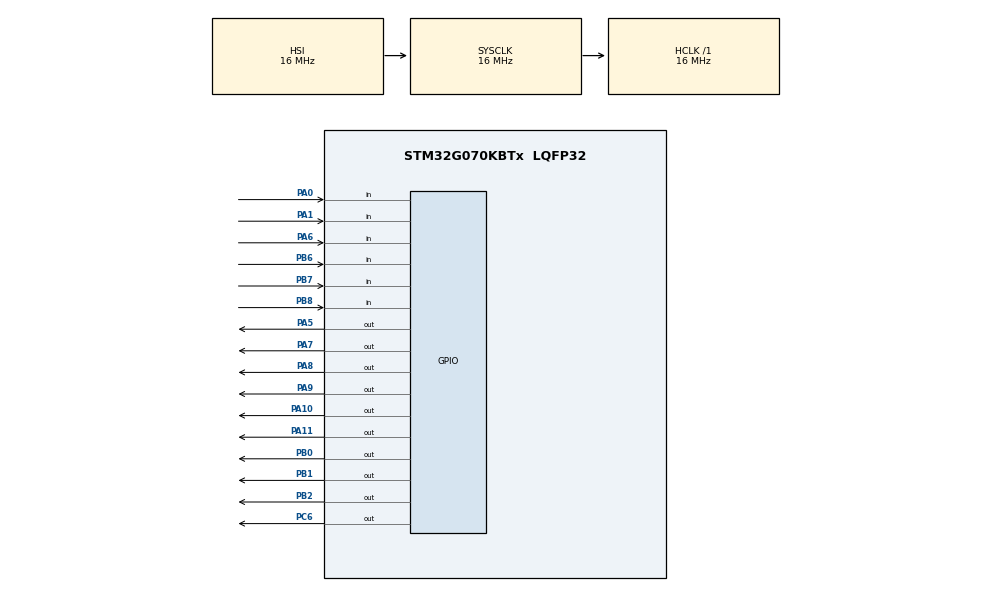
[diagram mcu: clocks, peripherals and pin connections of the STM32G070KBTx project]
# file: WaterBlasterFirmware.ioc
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Mcu.Family=STM32G0
Mcu.Name=STM32G070KBTx
Mcu.Package=LQFP32
PA0.Signal=GPIO_Input
PA1.Signal=GPIO_Input
PA10.Signal=GPIO_Output
PA11\ [PA9].Signal=GPIO_Output
PA13.Mode=Serial_Wire
PA13.Signal=SYS_SWDIO
PA14-BOOT0.Mode=Serial_Wire
PA14-BOOT0.Signal=SYS_SWCLK
PA5.Signal=GPIO_Output
PA6.Signal=GPIO_Input
PA7.Signal=GPIO_Output
PA8.Signal=GPIO_Output
PA9.Signal=GPIO_Output
PB0.Signal=GPIO_Output
PB1.Signal=GPIO_Output
PB2.Signal=GPIO_Output
PB6.Signal=GPIO_Input
PB7.Signal=GPIO_Input
PB8.Signal=GPIO_Input
PC6.Signal=GPIO_Output
ProjectManager.HeapSize=0x200
ProjectManager.StackSize=0x400
ProjectManager.TargetToolchain=STM32CubeIDE
RCC.AHBFreq_Value=16000000
RCC.CortexFreq_Value=16000000
RCC.EXTERNAL_CLOCK_VALUE=48000
RCC.HCLKFreq_Value=16000000
RCC.HSE_VALUE=8000000
RCC.HSI_VALUE=16000000
RCC.LSE_VALUE=32768
RCC.SYSCLKFreq_VALUE=16000000
RCC.VCOOutputFreq_Value=128000000
board=custom

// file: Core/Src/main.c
/* USER CODE BEGIN Header */
/**
  ******************************************************************************
  * @file           : main.c
  * @brief          : Main program body
  ******************************************************************************
  * @attention
  *
  * Copyright (c) 2025 STMicroelectronics.
  * All rights reserved.
  *
  * This software is licensed under terms that can be found in the LICENSE file
  * in the root directory of this software component.
  * If no LICENSE file comes with this software, it is provided AS-IS.
  *
  ******************************************************************************
  */
/* USER CODE END Header */
#include "main.h"
#include "newhaven_slim_oled.h"
#include "NHD_2066.h"
#include <stdio.h>
#include <string.h>

void SystemClock_Config(void);
static void MX_GPIO_Init(void);

/* USER CODE BEGIN PV */
uint8_t menu_mode = 0; // 0 = HOME, 1 = SETTINGS
uint8_t shot_count = 0;
uint32_t last_heartbeat = 0;
uint32_t last_valve_open_time = 0;
uint8_t valve_open = 0;
uint16_t valve_duration = 200;
uint8_t encoder_last_state = 0;

/* USER CODE END PV */

/* USER CODE BEGIN PFP */

ADC_HandleTypeDef hadc1;

int read_pressure_psi(void) {
    HAL_ADC_Start(&hadc1);

    if (HAL_ADC_PollForConversion(&hadc1, HAL_MAX_DELAY) != HAL_OK) {
        return -1;
    }

    uint32_t adc_raw_value = HAL_ADC_GetValue(&hadc1);
    float voltage = ((adc_raw_value * 3.3f) / 4095.0f) * 2.0f;

    if (voltage < 0.7f) voltage = 0.7f;
    if (voltage > 4.5f) voltage = 4.5f;

    float pressure = ((voltage - 0.7f) / 3.8f) * 150.0f;

    // Proper rounding for both positive and negative values
    if (pressure >= 0.0f)
        return (int)(pressure + 0.5f);
    else
        return (int)(pressure - 0.5f);
}

void update_heartbeat_led(void) {
    if (HAL_GetTick() - last_heartbeat >= 1000) {
        HAL_GPIO_TogglePin(GPIOC, GPIO_PIN_6);
        last_heartbeat = HAL_GetTick();
    }
}

void render_home_screen(int pressure) {
    NHD_OLED_textClear();
    char line[21];
    snprintf(line, sizeof(line), "Pressure: %3d PSI", pressure);
    NHD_OLED_print_len_pos(line, strlen(line), 0, 0);

    snprintf(line, sizeof(line), "Shots Remaining: %2d", shot_count);
    NHD_OLED_print_len_pos(line, strlen(line), 1, 0);

    int bar_len = (shot_count * 20) / 14;
    for (int i = 0; i < 20; ++i) {
        NHD_OLED_cursorPos(3, i);
        NHD_OLED_print_char(i < bar_len ? 0xFF : ' ');
    }
}

void render_settings_menu(void) {
    NHD_OLED_textClear();
    char line[21];
    snprintf(line, sizeof(line), "Burst Time: %4dms", valve_duration);
    NHD_OLED_print_len_pos(line, strlen(line), 1, 0);
    int bar_len = (valve_duration - 50) * 20 / (1000 - 50);
    for (int i = 0; i < 20; ++i) {
        NHD_OLED_cursorPos(3, i);
        NHD_OLED_print_char(i < bar_len ? 0xFF : ' ');
    }
}

int read_encoder_delta(void) {
    static uint8_t last_encoded = 0;
    uint8_t MSB = HAL_GPIO_ReadPin(GPIOA, GPIO_PIN_2);
    uint8_t LSB = HAL_GPIO_ReadPin(GPIOA, GPIO_PIN_3);
    uint8_t encoded = (MSB << 1) | LSB;
    uint8_t sum = (last_encoded << 2) | encoded;
    last_encoded = encoded;
    if (sum == 0b1101 || sum == 0b0100 || sum == 0b0010 || sum == 0b1011) return 1;
    if (sum == 0b1110 || sum == 0b0111 || sum == 0b0001 || sum == 0b1000) return -1;
    return 0;
}

void process_trigger(void) {
    if (shot_count > 0 && HAL_GPIO_ReadPin(GPIOA, GPIO_PIN_11) == GPIO_PIN_RESET) {
        HAL_GPIO_WritePin(GPIOA, GPIO_PIN_8, GPIO_PIN_SET);
        HAL_GPIO_WritePin(GPIOA, GPIO_PIN_9, GPIO_PIN_SET);
        last_valve_open_time = HAL_GetTick();
        valve_open = 1;
        shot_count--;
    }
    if (valve_open && HAL_GetTick() - last_valve_open_time >= valve_duration) {
        HAL_GPIO_WritePin(GPIOA, GPIO_PIN_8, GPIO_PIN_RESET);
        HAL_GPIO_WritePin(GPIOA, GPIO_PIN_9, GPIO_PIN_RESET);
        valve_open = 0;
    }
}

void process_pump(void) {
    if (HAL_GPIO_ReadPin(GPIOA, GPIO_PIN_1) == GPIO_PIN_RESET) {
        HAL_GPIO_WritePin(GPIOB, GPIO_PIN_2, GPIO_PIN_SET);
        HAL_GPIO_WritePin(GPIOA, GPIO_PIN_10, GPIO_PIN_SET);
    } else {
        HAL_GPIO_WritePin(GPIOB, GPIO_PIN_2, GPIO_PIN_RESET);
        HAL_GPIO_WritePin(GPIOA, GPIO_PIN_10, GPIO_PIN_RESET);
    }
}

void HAL_GPIO_EXTI_Callback(uint16_t GPIO_Pin) {
    if (GPIO_Pin == GPIO_PIN_4) {
        menu_mode ^= 1;
        HAL_Delay(200);
    }
}

int main(void)
{

  /* MCU Configuration--------------------------------------------------------*/

  /* Reset of all peripherals, Initializes the Flash interface and the Systick. */
  HAL_Init();

  /* Configure the system clock */
  SystemClock_Config();

  /* Initialize all configured peripherals */
  MX_GPIO_Init();

  /* Infinite loop */
  /* USER CODE BEGIN WHILE */
  HAL_GPIO_TogglePin(GPIOA, GPIO_PIN_10);
  /* USER CODE END 2 */

  /*
   * Set the reset to be high set
   * set the cs to be reset
   */
  HAL_GPIO_WritePin(GPIOB, GPIO_PIN_0, GPIO_PIN_RESET);
  HAL_GPIO_WritePin(GPIOB, GPIO_PIN_1, GPIO_PIN_SET);
//  HAL_GPIO_TogglePin(GPIOA, GPIO_PIN_8); // set the solenoid valve as closed on power on
  HAL_GPIO_TogglePin(GPIOA, GPIO_PIN_9); // set the solenoid valve as closed on power on
  NHD_OLED_begin();
  NHD_OLED_textClear();
  NHD_OLED_cursorHome();
  char* message = "Water Blaster";
  uint8_t length = 13;
  NHD_OLED_print_len(message, length);
  HAL_GPIO_TogglePin(GPIOA, GPIO_PIN_11);

  /* Infinite loop */
  /* USER CODE BEGIN WHILE */

////  NHD_OLED_displayOn();

  while (1==1)
  {

	if (HAL_GPIO_ReadPin(GPIOB, GPIO_PIN_6) == GPIO_PIN_RESET)
	{
	  HAL_GPIO_TogglePin(GPIOA, GPIO_PIN_9);
	  HAL_GPIO_TogglePin(GPIOA, GPIO_PIN_8);
	  HAL_Delay(50);
	  HAL_GPIO_TogglePin(GPIOA, GPIO_PIN_8);
	  HAL_GPIO_TogglePin(GPIOA, GPIO_PIN_9);
	}
	if (HAL_GPIO_ReadPin(GPIOA, GPIO_PIN_0) == GPIO_PIN_RESET)
	{
	  HAL_GPIO_TogglePin(GPIOB, GPIO_PIN_2);
	  HAL_GPIO_TogglePin(GPIOC, GPIO_PIN_6);
	  HAL_Delay(50);
	  HAL_GPIO_TogglePin(GPIOB, GPIO_PIN_2);
	  HAL_GPIO_TogglePin(GPIOC, GPIO_PIN_6);
	}
	if (HAL_GPIO_ReadPin(GPIOA, GPIO_PIN_1) == GPIO_PIN_RESET)
	{
	  HAL_GPIO_TogglePin(GPIOA, GPIO_PIN_9);
	  HAL_GPIO_TogglePin(GPIOA, GPIO_PIN_8);
	  HAL_GPIO_TogglePin(GPIOB, GPIO_PIN_2);
	  HAL_GPIO_TogglePin(GPIOC, GPIO_PIN_6);
	  HAL_Delay(50);
	  HAL_GPIO_TogglePin(GPIOB, GPIO_PIN_2);
	  HAL_GPIO_TogglePin(GPIOC, GPIO_PIN_6);
	  HAL_GPIO_TogglePin(GPIOA, GPIO_PIN_8);
	  HAL_GPIO_TogglePin(GPIOA, GPIO_PIN_9);
	}
	}
  /* USER CODE END 3 */
}

void SystemClock_Config(void)
{
  RCC_OscInitTypeDef RCC_OscInitStruct = {0};
  RCC_ClkInitTypeDef RCC_ClkInitStruct = {0};

  /** Configure the main internal regulator output voltage
  */
  HAL_PWREx_ControlVoltageScaling(PWR_REGULATOR_VOLTAGE_SCALE1);

  /** Initializes the RCC Oscillators according to the specified parameters
  * in the RCC_OscInitTypeDef structure.
  */
  RCC_OscInitStruct.OscillatorType = RCC_OSCILLATORTYPE_HSI;
  RCC_OscInitStruct.HSIState = RCC_HSI_ON;
  RCC_OscInitStruct.HSIDiv = RCC_HSI_DIV1;
  RCC_OscInitStruct.HSICalibrationValue = RCC_HSICALIBRATION_DEFAULT;
  RCC_OscInitStruct.PLL.PLLState = RCC_PLL_NONE;
  if (HAL_RCC_OscConfig(&RCC_OscInitStruct) != HAL_OK)
  {
    Error_Handler();
  }

  /** Initializes the CPU, AHB and APB buses clocks
  */
  RCC_ClkInitStruct.ClockType = RCC_CLOCKTYPE_HCLK|RCC_CLOCKTYPE_SYSCLK
                              |RCC_CLOCKTYPE_PCLK1;
  RCC_ClkInitStruct.SYSCLKSource = RCC_SYSCLKSOURCE_HSI;
  RCC_ClkInitStruct.AHBCLKDivider = RCC_SYSCLK_DIV1;
  RCC_ClkInitStruct.APB1CLKDivider = RCC_HCLK_DIV1;

  if (HAL_RCC_ClockConfig(&RCC_ClkInitStruct, FLASH_LATENCY_0) != HAL_OK)
  {
    Error_Handler();
  }
}

static void MX_GPIO_Init(void)
{
  GPIO_InitTypeDef GPIO_InitStruct = {0};

  /* GPIO Ports Clock Enable */
  __HAL_RCC_GPIOA_CLK_ENABLE();
  __HAL_RCC_GPIOB_CLK_ENABLE();
  __HAL_RCC_GPIOC_CLK_ENABLE();

  /*Configure GPIO pin Output Level */
  HAL_GPIO_WritePin(GPIOA, GPIO_PIN_5|GPIO_PIN_7|GPIO_PIN_8|GPIO_PIN_9
                          |GPIO_PIN_10|GPIO_PIN_11, GPIO_PIN_RESET);

  /*Configure GPIO pin Output Level */
  HAL_GPIO_WritePin(GPIOB, GPIO_PIN_0|GPIO_PIN_1|GPIO_PIN_2, GPIO_PIN_RESET);

  /*Configure GPIO pin Output Level */
  HAL_GPIO_WritePin(GPIOC, GPIO_PIN_6, GPIO_PIN_RESET);

  /*Configure GPIO pins : PA0 PA1 PA6 */
  GPIO_InitStruct.Pin = GPIO_PIN_0|GPIO_PIN_1|GPIO_PIN_6;
  GPIO_InitStruct.Mode = GPIO_MODE_INPUT;
  GPIO_InitStruct.Pull = GPIO_NOPULL;
  HAL_GPIO_Init(GPIOA, &GPIO_InitStruct);

  /*Configure GPIO pins : PA5 PA7 PA8 PA9
                           PA10 PA11 */
  GPIO_InitStruct.Pin = GPIO_PIN_5|GPIO_PIN_7|GPIO_PIN_8|GPIO_PIN_9
                          |GPIO_PIN_10|GPIO_PIN_11;
  GPIO_InitStruct.Mode = GPIO_MODE_OUTPUT_PP;
  GPIO_InitStruct.Pull = GPIO_NOPULL;
  GPIO_InitStruct.Speed = GPIO_SPEED_FREQ_LOW;
  HAL_GPIO_Init(GPIOA, &GPIO_InitStruct);

  /*Configure GPIO pins : PB0 PB1 PB2 */
  GPIO_InitStruct.Pin = GPIO_PIN_0|GPIO_PIN_1|GPIO_PIN_2;
  GPIO_InitStruct.Mode = GPIO_MODE_OUTPUT_PP;
  GPIO_InitStruct.Pull = GPIO_NOPULL;
  GPIO_InitStruct.Speed = GPIO_SPEED_FREQ_LOW;
  HAL_GPIO_Init(GPIOB, &GPIO_InitStruct);

  /*Configure GPIO pin : PC6 */
  GPIO_InitStruct.Pin = GPIO_PIN_6;
  GPIO_InitStruct.Mode = GPIO_MODE_OUTPUT_PP;
  GPIO_InitStruct.Pull = GPIO_NOPULL;
  GPIO_InitStruct.Speed = GPIO_SPEED_FREQ_LOW;
  HAL_GPIO_Init(GPIOC, &GPIO_InitStruct);

  /*Configure GPIO pins : PB6 PB7 PB8 */
  GPIO_InitStruct.Pin = GPIO_PIN_6|GPIO_PIN_7|GPIO_PIN_8;
  GPIO_InitStruct.Mode = GPIO_MODE_INPUT;
  GPIO_InitStruct.Pull = GPIO_NOPULL;
  HAL_GPIO_Init(GPIOB, &GPIO_InitStruct);

}

void Error_Handler(void)
{
  __disable_irq();
  while (1)
  {
  }
}
